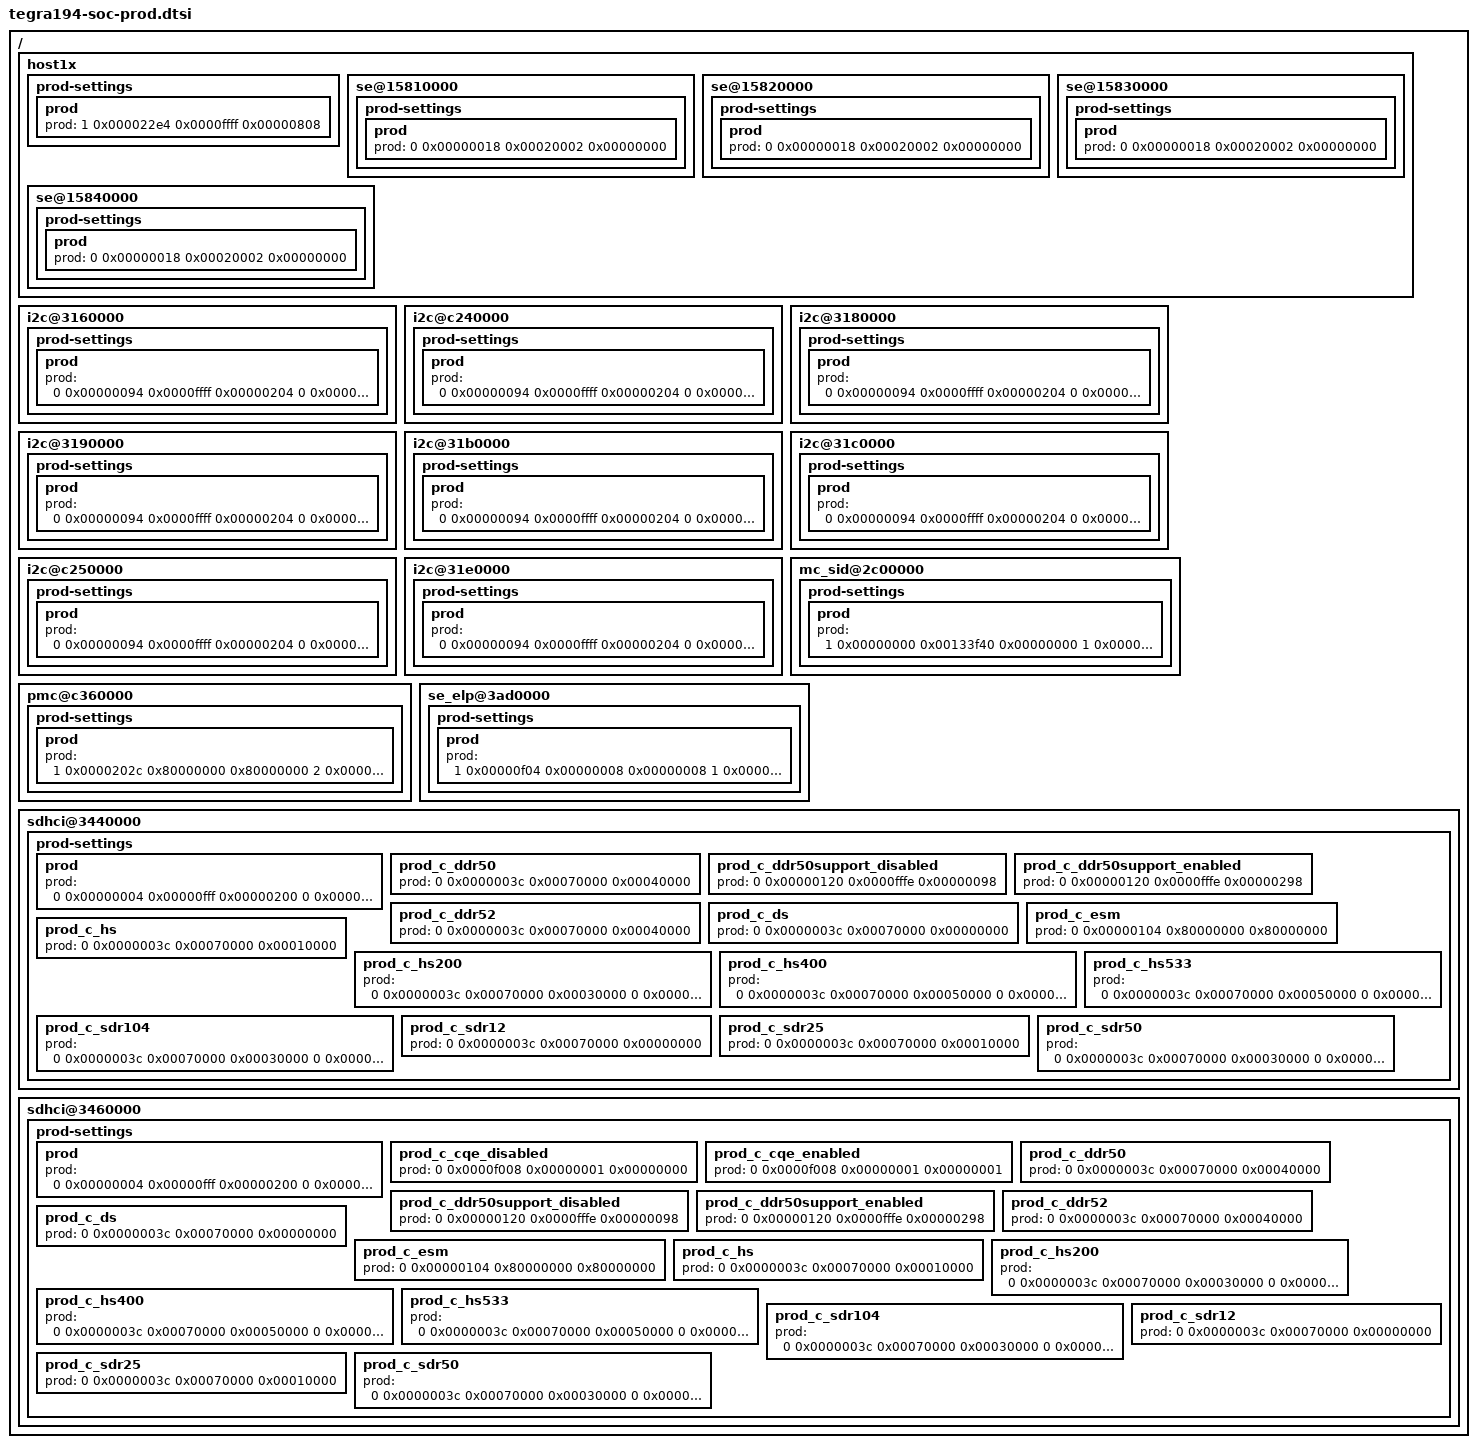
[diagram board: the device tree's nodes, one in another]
/*
 * Copyright (c) 2017, NVIDIA CORPORATION.  All rights reserved.
 *
 * This program is free software; you can redistribute it and/or modify
 * it under the terms of the GNU General Public License as published by
 * the Free Software Foundation; version 2 of the License.
 *
 * This program is distributed in the hope that it will be useful, but WITHOUT
 * ANY WARRANTY; without even the implied warranty of MERCHANTABILITY or
 * FITNESS FOR A PARTICULAR PURPOSE.  See the GNU General Public License for
 * more details.
 *
 * You should have received a copy of the GNU General Public License along
 * with this program; if not, write to the Free Software Foundation, Inc.,
 * 51 Franklin Street, Fifth Floor, Boston, MA  02110-1301, USA.
 *
 */
/*
* tegra194-soc-prod.dtsi: soc specific Prod configuration.
* Generation date: 2017-11-07 12:20
* PLEASE DO NOT EDIT THIS FILE MANUALLY
* This file is autogenerated using the script gen_prod_dtsi.py V1.2
* NOTE: Do not use file as is. Copy the relevant section to existing file in tree.
* NOTE: FIXME nodes indicate nodes corresponding to Golden Register were not found in input DTB.
*       Please check if DTB has the nodes enabled and register address in GR DB is valid.
*/

/ {
	host1x {
		prod-settings {
			#prod-cells = <4>;
			prod {
				prod = <
					1 0x000022e4 0x0000ffff 0x00000808>;            //HOST1X_THOST_COMMON_CDMA_ASM_TIMEOUT_0
			};
		};
		se@15810000 {
			prod-settings {
				#prod-cells = <4>;
				prod {
					prod = <
						0 0x00000018 0x00020002 0x00000000>;            //SE1_SE_SECURITY_0
				};
			};
		};

		se@15820000 {
			prod-settings {
				#prod-cells = <4>;
				prod {
					prod = <
						0 0x00000018 0x00020002 0x00000000>;            //SE2_SE_SECURITY_0
				};
			};
		};

		se@15830000 {
			prod-settings {
				#prod-cells = <4>;
				prod {
					prod = <
						0 0x00000018 0x00020002 0x00000000>;            //SE3_SE_SECURITY_0
				};
			};
		};

		se@15840000 {
			prod-settings {
				#prod-cells = <4>;
				prod {
					prod = <
						0 0x00000018 0x00020002 0x00000000>;            //SE4_SE_SECURITY_0
				};
			};
		};
	};

	i2c@3160000 {
		prod-settings {
			#prod-cells = <4>;
			prod {
				prod = <
					0 0x00000094 0x0000ffff 0x00000204              //I2C_I2C_INTERFACE_TIMING_0_0
					0 0x00000098 0xffffffff 0x04070404              //I2C_I2C_INTERFACE_TIMING_1_0
					0 0x0000009c 0x0000ffff 0x00000308              //I2C_I2C_HS_INTERFACE_TIMING_0_0
					0 0x000000a0 0x00ffffff 0x000b0b0b              //I2C_I2C_HS_INTERFACE_TIMING_1_0
					0 0x000000d4 0x000000ff 0x00000000              //I2C_I2C_INTERFACE_TIMING_2_0
					0 0x000000d8 0x000000ff 0x00000000              //I2C_I2C_HS_INTERFACE_TIMING_2_0
					0 0x000000dc 0x0000ffff 0x00000001              //I2C_I2C_MSTR_DATA_CAPTURE_TIMING_0
					0 0x000000e0 0x0000ffff 0x00000002>;            //I2C_I2C_SLV_DATA_CAPTURE_TIMING_0
			};
		};
	};

	i2c@c240000 {
		prod-settings {
			#prod-cells = <4>;
			prod {
				prod = <
					0 0x00000094 0x0000ffff 0x00000204              //I2C_I2C_INTERFACE_TIMING_0_0
					0 0x00000098 0xffffffff 0x04070404              //I2C_I2C_INTERFACE_TIMING_1_0
					0 0x0000009c 0x0000ffff 0x00000308              //I2C_I2C_HS_INTERFACE_TIMING_0_0
					0 0x000000a0 0x00ffffff 0x000b0b0b              //I2C_I2C_HS_INTERFACE_TIMING_1_0
					0 0x000000d4 0x000000ff 0x00000000              //I2C_I2C_INTERFACE_TIMING_2_0
					0 0x000000d8 0x000000ff 0x00000000              //I2C_I2C_HS_INTERFACE_TIMING_2_0
					0 0x000000dc 0x0000ffff 0x00000001              //I2C_I2C_MSTR_DATA_CAPTURE_TIMING_0
					0 0x000000e0 0x0000ffff 0x00000002>;            //I2C_I2C_SLV_DATA_CAPTURE_TIMING_0
			};
		};
	};

	i2c@3180000 {
		prod-settings {
			#prod-cells = <4>;
			prod {
				prod = <
					0 0x00000094 0x0000ffff 0x00000204              //I2C_I2C_INTERFACE_TIMING_0_0
					0 0x00000098 0xffffffff 0x04070404              //I2C_I2C_INTERFACE_TIMING_1_0
					0 0x0000009c 0x0000ffff 0x00000308              //I2C_I2C_HS_INTERFACE_TIMING_0_0
					0 0x000000a0 0x00ffffff 0x000b0b0b              //I2C_I2C_HS_INTERFACE_TIMING_1_0
					0 0x000000d4 0x000000ff 0x00000000              //I2C_I2C_INTERFACE_TIMING_2_0
					0 0x000000d8 0x000000ff 0x00000000              //I2C_I2C_HS_INTERFACE_TIMING_2_0
					0 0x000000dc 0x0000ffff 0x00000001              //I2C_I2C_MSTR_DATA_CAPTURE_TIMING_0
					0 0x000000e0 0x0000ffff 0x00000002>;            //I2C_I2C_SLV_DATA_CAPTURE_TIMING_0
			};
		};
	};

	i2c@3190000 {
		prod-settings {
			#prod-cells = <4>;
			prod {
				prod = <
					0 0x00000094 0x0000ffff 0x00000204              //I2C_I2C_INTERFACE_TIMING_0_0
					0 0x00000098 0xffffffff 0x04070404              //I2C_I2C_INTERFACE_TIMING_1_0
					0 0x0000009c 0x0000ffff 0x00000308              //I2C_I2C_HS_INTERFACE_TIMING_0_0
					0 0x000000a0 0x00ffffff 0x000b0b0b              //I2C_I2C_HS_INTERFACE_TIMING_1_0
					0 0x000000d4 0x000000ff 0x00000000              //I2C_I2C_INTERFACE_TIMING_2_0
					0 0x000000d8 0x000000ff 0x00000000              //I2C_I2C_HS_INTERFACE_TIMING_2_0
					0 0x000000dc 0x0000ffff 0x00000001              //I2C_I2C_MSTR_DATA_CAPTURE_TIMING_0
					0 0x000000e0 0x0000ffff 0x00000002>;            //I2C_I2C_SLV_DATA_CAPTURE_TIMING_0
			};
		};
	};

	i2c@31b0000 {
		prod-settings {
			#prod-cells = <4>;
			prod {
				prod = <
					0 0x00000094 0x0000ffff 0x00000204              //I2C_I2C_INTERFACE_TIMING_0_0
					0 0x00000098 0xffffffff 0x04070404              //I2C_I2C_INTERFACE_TIMING_1_0
					0 0x0000009c 0x0000ffff 0x00000308              //I2C_I2C_HS_INTERFACE_TIMING_0_0
					0 0x000000a0 0x00ffffff 0x000b0b0b              //I2C_I2C_HS_INTERFACE_TIMING_1_0
					0 0x000000d4 0x000000ff 0x00000000              //I2C_I2C_INTERFACE_TIMING_2_0
					0 0x000000d8 0x000000ff 0x00000000              //I2C_I2C_HS_INTERFACE_TIMING_2_0
					0 0x000000dc 0x0000ffff 0x00000001              //I2C_I2C_MSTR_DATA_CAPTURE_TIMING_0
					0 0x000000e0 0x0000ffff 0x00000002>;            //I2C_I2C_SLV_DATA_CAPTURE_TIMING_0
			};
		};
	};

	i2c@31c0000 {
		prod-settings {
			#prod-cells = <4>;
			prod {
				prod = <
					0 0x00000094 0x0000ffff 0x00000204              //I2C_I2C_INTERFACE_TIMING_0_0
					0 0x00000098 0xffffffff 0x04070404              //I2C_I2C_INTERFACE_TIMING_1_0
					0 0x0000009c 0x0000ffff 0x00000308              //I2C_I2C_HS_INTERFACE_TIMING_0_0
					0 0x000000a0 0x00ffffff 0x000b0b0b              //I2C_I2C_HS_INTERFACE_TIMING_1_0
					0 0x000000d4 0x000000ff 0x00000000              //I2C_I2C_INTERFACE_TIMING_2_0
					0 0x000000d8 0x000000ff 0x00000000              //I2C_I2C_HS_INTERFACE_TIMING_2_0
					0 0x000000dc 0x0000ffff 0x00000001              //I2C_I2C_MSTR_DATA_CAPTURE_TIMING_0
					0 0x000000e0 0x0000ffff 0x00000002>;            //I2C_I2C_SLV_DATA_CAPTURE_TIMING_0
			};
		};
	};

	i2c@c250000 {
		prod-settings {
			#prod-cells = <4>;
			prod {
				prod = <
					0 0x00000094 0x0000ffff 0x00000204              //I2C_I2C_INTERFACE_TIMING_0_0
					0 0x00000098 0xffffffff 0x04070404              //I2C_I2C_INTERFACE_TIMING_1_0
					0 0x0000009c 0x0000ffff 0x00000308              //I2C_I2C_HS_INTERFACE_TIMING_0_0
					0 0x000000a0 0x00ffffff 0x000b0b0b              //I2C_I2C_HS_INTERFACE_TIMING_1_0
					0 0x000000d4 0x000000ff 0x00000000              //I2C_I2C_INTERFACE_TIMING_2_0
					0 0x000000d8 0x000000ff 0x00000000              //I2C_I2C_HS_INTERFACE_TIMING_2_0
					0 0x000000dc 0x0000ffff 0x00000001              //I2C_I2C_MSTR_DATA_CAPTURE_TIMING_0
					0 0x000000e0 0x0000ffff 0x00000002>;            //I2C_I2C_SLV_DATA_CAPTURE_TIMING_0
			};
		};
	};

	i2c@31e0000 {
		prod-settings {
			#prod-cells = <4>;
			prod {
				prod = <
					0 0x00000094 0x0000ffff 0x00000204              //I2C_I2C_INTERFACE_TIMING_0_0
					0 0x00000098 0xffffffff 0x04070404              //I2C_I2C_INTERFACE_TIMING_1_0
					0 0x0000009c 0x0000ffff 0x00000308              //I2C_I2C_HS_INTERFACE_TIMING_0_0
					0 0x000000a0 0x00ffffff 0x000b0b0b              //I2C_I2C_HS_INTERFACE_TIMING_1_0
					0 0x000000d4 0x000000ff 0x00000000              //I2C_I2C_INTERFACE_TIMING_2_0
					0 0x000000d8 0x000000ff 0x00000000              //I2C_I2C_HS_INTERFACE_TIMING_2_0
					0 0x000000dc 0x0000ffff 0x00000001              //I2C_I2C_MSTR_DATA_CAPTURE_TIMING_0
					0 0x000000e0 0x0000ffff 0x00000002>;            //I2C_I2C_SLV_DATA_CAPTURE_TIMING_0
			};
		};
	};

	mc_sid@2c00000 {
		prod-settings {
			#prod-cells = <4>;
			prod {
				prod = <
					1 0x00000000 0x00133f40 0x00000000              //MC_INTSTATUS_0
					1 0x00000004 0x001f3f40 0x00000000              //MC_INTMASK_0
					1 0x00000010 0x00000001 0x00000000              //MC_SMMU_CONFIG_0
					1 0x00000014 0xf000003f 0x30000030              //MC_SMMU_TLB_CONFIG_0
					1 0x00000018 0xe03f0fff 0x20220f3f              //MC_SMMU_PTC_CONFIG_0
					1 0x00000030 0x00100000 0x00000000              //MC_SMMU_TLB_FLUSH_0
					1 0x00000034 0x00000008 0x00000008              //MC_SMMU_PTC_FLUSH_0
					1 0x00000038 0xffffffff 0x00000000              //MC_SMMU_ASID_SECURITY_0
					1 0x00000050 0x80000000 0x00000000              //MC_EMEM_CFG_0
					1 0x00000070 0xfff00000 0x80000000              //MC_SECURITY_CFG0_0
					1 0x00000074 0x00001fff 0x00000000              //MC_SECURITY_CFG1_0
					1 0x0000007c 0xffffffff 0xff00ff00              //MC_SECURITY_RSV_0
					1 0x00000090 0xff000000 0x00000000              //MC_EMEM_ARB_CFG_0
					1 0x000000bc 0x0000003f 0x0000003f              //MC_EMEM_ARB_TIMING_W2W_0
					1 0x000000c8 0xf0ff0ffe 0xb00a0402              //MC_EMEM_ARB_MISC2_0
					1 0x000000cc 0x00000003 0x00000000              //MC_CLKEN_A1_OVERRIDE_0
					1 0x000000d8 0x7fe080ff 0x72000010              //MC_EMEM_ARB_MISC0_0
					1 0x000000dc 0x0000fffd 0x00000008              //MC_EMEM_ARB_MISC1_0
					1 0x000000e0 0x003f003f 0x003f0000              //MC_EMEM_ARB_RING1_THROTTLE_0
					1 0x000000e4 0x001f001f 0x00000000              //MC_EMEM_ARB_RING3_THROTTLE_0
					1 0x000000e8 0x8cffff18 0x00000000              //MC_EMEM_ARB_OVERRIDE_0
					1 0x000000ec 0xffffffff 0xff00ff00              //MC_EMEM_ARB_RSV_0
					1 0x000000f4 0xffffffed 0x00000000              //MC_CLKEN_OVERRIDE_0
					1 0x000000f8 0x0000001f 0x00000000              //MC_TIMING_CONTROL_DBG_0
					1 0x00000154 0x00000001 0x00000000              //MC_SECURITY_CFG_REG_CTRL_0
					1 0x000001c0 0x00007f33 0x00000030              //MC_STAT_EMC_SET0_IDLE_CYCLE_PARTITION_SELECT_0
					1 0x000001d0 0x00007f33 0x00000030              //MC_STAT_EMC_SET1_IDLE_CYCLE_PARTITION_SELECT_0
					1 0x000001ec 0x8000ffff 0x80000000              //MC_SMMU_STATS_TLB_HIT_MISS_SOURCE_0
					1 0x0000023c 0xf0ff7f7f 0xf0551010              //MC_EMEM_ARB_MISC3_0
					1 0x00000240 0x0000f7ff 0x00007010              //MC_EMEM_ARB_MISC4_0
					1 0x000003fc 0xf0000000 0xf0000000              //MC_RESERVED_RSV_0
					1 0x00000564 0x0fffffff 0x00000000              //MC_IGPU_ACCESSIBLE_CARVEOUT1_SIZE_0
					1 0x0000056c 0x0fffffff 0x00000000              //MC_IGPU_ACCESSIBLE_CARVEOUT2_SIZE_0
					1 0x000005a4 0x0fffffff 0x00000000              //MC_REMOTE_DEV_ACCESSIBLE_CARVEOUT1_SIZE_0
					1 0x000005ac 0x0fffffff 0x00000000              //MC_REMOTE_DEV_ACCESSIBLE_CARVEOUT2_SIZE_0
					1 0x0000066c 0xc00003ff 0x80000080              //MC_EMEM_ARB_OUTSTANDING_REQ_RING3_0
					1 0x000006b0 0x803f003f 0x003f0000              //MC_EMEM_ARB_NISO_THROTTLE_0
					1 0x000006b4 0xc00003ff 0x00000080              //MC_EMEM_ARB_OUTSTANDING_REQ_NISO_0
					1 0x000006bc 0x800080c5 0x80008041              //MC_EMEM_ARB_RING0_THROTTLE_MASK_0
					1 0x000006f0 0x007f7f7f 0x000a1020              //MC_EMEM_ARB_REFPB_HP_CTRL_0
					1 0x000006f4 0x00007f7f 0x00002636              //MC_EMEM_ARB_REFPB_BANK_CTRL_0
					1 0x00000958 0xffffffff 0xff00ff00              //MC_RESERVED_RSV_1_0
					1 0x00000960 0x00001fff 0x00001000              //MC_PTSA_GRANT_DECREMENT_0
					1 0x00000968 0x000018a0 0x00000080              //MC_EMEM_ARB_OVERRIDE_1_0
					1 0x00000984 0xffffffff 0x00000000              //MC_VIDEO_PROTECT_GPU_OVERRIDE_0_0
					1 0x00000988 0x0000ffff 0x00000000              //MC_VIDEO_PROTECT_GPU_OVERRIDE_1_0
					1 0x00000990 0x003f003f 0x003f0004              //MC_EMEM_ARB_STATS_0_0
					1 0x00000994 0x003f003f 0x003f0004              //MC_EMEM_ARB_STATS_1_0
					1 0x000009a4 0x00000fff 0x00000000              //MC_MTS_CARVEOUT_SIZE_MB_0
					1 0x000009bc 0x000000ff 0x00000000              //MC_SECURITY_CFG3_0
					1 0x000009d0 0x00030000 0x00000000              //MC_ERR_APB_ASID_UPDATE_STATUS_0
					1 0x000009fc 0xb790f3ff 0x9680f183              //MC_EMEM_ARB_DA_HYSTERESIS_0
					1 0x00000bcc 0x00000003 0x00000002              //MC_EMEM_ARB_DHYST_CTRL_0
					1 0x00000bd0 0x00000fff 0x00000100              //MC_EMEM_ARB_DHYST_TIMEOUT_UTIL_0_0
					1 0x00000bd4 0x00000fff 0x000000a0              //MC_EMEM_ARB_DHYST_TIMEOUT_UTIL_1_0
					1 0x00000bd8 0x00000fff 0x00000060              //MC_EMEM_ARB_DHYST_TIMEOUT_UTIL_2_0
					1 0x00000bdc 0x00000fff 0x00000034              //MC_EMEM_ARB_DHYST_TIMEOUT_UTIL_3_0
					1 0x00000be0 0x00000fff 0x00000018              //MC_EMEM_ARB_DHYST_TIMEOUT_UTIL_4_0
					1 0x00000be4 0x00000fff 0x0000000c              //MC_EMEM_ARB_DHYST_TIMEOUT_UTIL_5_0
					1 0x00000be8 0x00000fff 0x00000004              //MC_EMEM_ARB_DHYST_TIMEOUT_UTIL_6_0
					1 0x00000bec 0x00000fff 0x00000000              //MC_EMEM_ARB_DHYST_TIMEOUT_UTIL_7_0
					1 0x00000e54 0x00080200 0x00000000              //MC_CH_INTSTATUS_0
					1 0x00000e5c 0x000007ff 0x00000003              //MC_LATENCY_ALLOWANCE_WCAM_0
					1 0x00000e60 0x00010000 0x00010000              //MC_CFG_WCAM_0
					1 0x00000e64 0xff0f0f0f 0x00000000              //MC_WCAM_ENCR_KEY_STATUS_0
					1 0x00000eb0 0x00000081 0x00000001              //MC_WCAM_STATE_0
					1 0x00000ec4 0x001f3f40 0x00000000              //MC_INTPRIORITY_0
					1 0x00000ed0 0x00000002 0x00000000              //MC_TR_BIT_CTL_0
					1 0x00000ed4 0x00000001 0x00000000              //MC_CFG_WCAM_GOB_REMAP_0
					1 0x00000edc 0x7f7f0001 0x00000000              //MC_WCAM_IRQ_TEST_0
					1 0x00000ee0 0x0fffffff 0x00000000              //MC_WCAM_IRQ_P0_STATUS0_0
					1 0x00000ee4 0xfffffff8 0x00000000              //MC_WCAM_IRQ_P0_STATUS1_0
					1 0x00000ee8 0x0fffffff 0x00000000              //MC_WCAM_IRQ_P1_STATUS0_0
					1 0x00000eec 0xfffffff8 0x00000000              //MC_WCAM_IRQ_P1_STATUS1_0
					1 0x00000f24 0x07ff0fff 0x00000000              //MC_GLOBAL_INTSTATUS_0
					1 0x00000f28 0x03ff0fff 0x00000000              //MC_GLOBAL_CRITICAL_INTSTATUS_0
					1 0x00000f2c 0x00000001 0x00000000              //MC_HUBC_INTSTATUS_0
					1 0x00000f38 0xe03f1fff 0x20221f3f              //MC_SMMU_NVCACHE_CONFIG_0
					1 0x00000f3c 0x00000001 0x00000000              //MC_CCITRX_ENABLE_CONFIG_0
					1 0x00000f40 0x000000ff 0x00000080              //MC_CCI_WR_LATENCY_ALLOWANCE_CONFIG_0
					1 0x00000f48 0x000007ff 0x00000000              //MC_SMMU_NVCACHE_ALLOWANCE_0
					1 0x00000f4c 0x00000007 0x00000001              //MC_SMMU_TCU_WRAP_CONFIG_0
					1 0x00000f50 0x00000003 0x00000000              //MC_HUB_INTMASK_0
					1 0x00000f54 0x00000003 0x00000000              //MC_HUB_INTPRIORITY_0
					1 0x00000f58 0x00000003 0x00000000              //MC_HUB_INTSTATUS_0
					1 0x00000f60 0x8000000f 0x80000000              //MC_CIFLL_MISC0_0
					1 0x00000f64 0x800f0fff 0x800c0019              //MC_CIFLL_REDEADLINE0_0
					1 0x00000f68 0x800f0fff 0x800c0004              //MC_CIFLL_REDEADLINE1_0
					1 0x00000fa0 0x00000001 0x00000000              //MC_HUB_CLKEN_OVERRIDE_0
					1 0x00000fa4 0x3fffffff 0x16286840              //MC_HUB_VCTHROTTLE_OVERRIDE_0
					1 0x00000fe8 0x00000001 0x00000001              //MC_CONFIG_TSA_SINGLE_ARB_ENABLE_0
					1 0x00000fec 0x00000007 0x00000007              //MC_DBB_RINGFENCE_CTRL_0
					1 0x00001840 0x800003ff 0x8000006e              //MC_MAX_OUTSTANDING_CCI_0
					1 0x00001850 0xfffff000 0x40000000              //MC_SYSRAM_BOM_0
					1 0x00001854 0xfffff000 0x40067000              //MC_SYSRAM_TOM_0
					1 0x00001860 0x000fffff 0x00020000              //MC_MSSNVLINK_BOM_0
					1 0x00001864 0x000fffff 0x00000000              //MC_MSSNVLINK_TOM_0
					1 0x00001870 0x000fffff 0x00000600              //MC_SYNCPOINT_BOM_0
					1 0x00001874 0x000fffff 0x00000603              //MC_SYNCPOINT_TOM_0
					1 0x00001890 0x000007ff 0x00000020              //MC_MSSNVLINK_IGPU_LATENCY_ALLOWANCE_0
					1 0x00001894 0x000007ff 0x00000020              //MC_MSSNVLINK_DGPU_LATENCY_ALLOWANCE_0
					1 0x0000189c 0x000007ff 0x00000000              //MC_CIFLL_NVLRHP_LATENCY_ALLOWANCE_0
					1 0x000018b8 0x00000001 0x00000001              //MC_MC_TBU_TRANSACTION_ATTR_CTRL_0
					1 0x0000193c 0x00000003 0x00000000              //MC_CLIENT_CCI_CAPABLE_7_0
					1 0x00001b00 0xffffffff 0x00000000              //MC_HUB_STATS_PM_COUNT0WORD0_0
					1 0x00002958 0x800003ff 0x00000040              //MC_MC_SMMU_ARB_MAX_OUTSTANDING_NISO_0
					1 0x0000295c 0x800003ff 0x00000040              //MC_MC_SMMU_ARB_MAX_OUTSTANDING_SISO_0
					1 0x00002960 0x800003ff 0x00000040              //MC_MC_SMMU_ARB_MAX_OUTSTANDING_ISO_0
					1 0x00002964 0x0000007f 0x0000003f              //MC_MC_SMMU_ARB_MAX_THROTTLE_0
					1 0x00002968 0x00000301 0x00000001              //MC_MC_SMMU_ISO_TBU_CCHK_REQ_PRI_CTRL_0
					1 0x000037e0 0x000000ff 0x00000000              //MC_GLOBAL_INTSTATUS_1_0
					1 0x000037e4 0x000000ff 0x00000000              //MC_GLOBAL_CRITICAL_INTSTATUS_1_0
					1 0x00008010 0x0000001f 0x00000000              //MC_MCF_ORSPX_CLKEN_OVERRIDE_0
					1 0x00008014 0x00007fff 0x00000000              //MC_MCF_IRSPX_CLKEN_OVERRIDE_0
					1 0x00008114 0x0000003f 0x00000000              //MC_MCF_IREQX_CLKEN_OVERRIDE_0
					1 0x00008118 0x0000003f 0x00000000              //MC_MCF_OREQX_CLKEN_OVERRIDE_0
					1 0x00008300 0x00070003 0x00020000              //MC_MCF_SLICE_CFG_0
					1 0x00008324 0x0000003f 0x00000000              //MC_MCF_SLICE_CLKEN_OVERRIDE_0
					1 0x00008c04 0x0000000f 0x00000000              //MC_MSS_SYSRAM_CLKEN_OVERRIDE_0
					1 0x00008f08 0x00000007 0x00000000              //MC_MSS_SBS_INTSTATUS_0
					1 0x00008f0c 0x00000007 0x00000000              //MC_MSS_SBS_INTMASK_0
					1 0x00008f10 0x00000007 0x00000000>;            //MC_MSS_SBS_CLKEN_OVERRIDE_0
			};
		};
	};

	pmc@c360000 {
		prod-settings {
			#prod-cells = <4>;
			prod {
				prod = <
					1 0x0000202c 0x80000000 0x80000000              //SCRATCH_SCRATCH0_ECO_0
					2 0x00000010 0x00000001 0x00000001>;            //PMC_MISC_FUSE_CONTROL_0
			};
		};
	};

	se_elp@3ad0000 {
		prod-settings {
			#prod-cells = <4>;
			prod {
				prod = <
					1 0x00000f04 0x00000008 0x00000008              //SE_RNG1_RNG1_MODE_0
					1 0x00000f08 0x00000002 0x00000002              //SE_RNG1_RNG1_SMODE_0
					1 0x00000fec 0x00000002 0x00000000>;            //SE_RNG1_RNG1_SECURITY_0
			};
		};
	};

	sdhci@3440000 {
		prod-settings {
			#prod-cells = <4>;
			prod {
				prod = <
					0 0x00010004 0x00000fff 0x00000200              //SDMMC_BLOCK_SIZE_BLOCK_COUNT_0
					0 0x00010028 0x00000022 0x00000002              //SDMMC_POWER_CONTROL_HOST_0
					0 0x0001002c 0x000f0000 0x000e0000              //SDMMC_SW_RESET_TIMEOUT_CTRL_CLOCK_CONTROL_0
					0 0x00010100 0x1fff0048 0x050b0000              //SDMMC_VENDOR_CLOCK_CNTRL_0
					0 0x00010104 0x80000000 0x00000000              //SDMMC_VENDOR_SYS_SW_CNTRL_0
					0 0x00010128 0x42000000 0x00000000              //SDMMC_VENDOR_MISC_CNTRL2_0
					0 0x000101c0 0x00001fc0 0x00000040              //SDMMC_VENDOR_TUNING_CNTRL0_0
					0 0x000101c4 0x0003ff77 0x00000400              //SDMMC_VENDOR_TUNING_CNTRL1_0
					0 0x000101e0 0x80000000 0x00000000              //SDMMC_SDMEMCOMPPADCTRL_0
					0 0x000101e4 0x20007f00 0x20007a00              //SDMMC_AUTO_CAL_CONFIG_0
					0 0x00010204 0x80000000 0x00000000>;            //SDMMC_VENDOR_MISC_CNTRL3_0
			};
			prod_c_ddr50 {
				prod = <
					0 0x0001003c 0x00070000 0x00040000>;            //SDMMC_AUTO_CMD12_ERR_STATUS_0
			};
			prod_c_ddr50support_disabled {
				prod = <
					0 0x00010120 0x0000fffe 0x00000098>;            //SDMMC_VENDOR_MISC_CNTRL_0
			};
			prod_c_ddr50support_enabled {
				prod = <
					0 0x00010120 0x0000fffe 0x00000298>;            //SDMMC_VENDOR_MISC_CNTRL_0
			};
			prod_c_ddr52 {
				prod = <
					0 0x0001003c 0x00070000 0x00040000>;            //SDMMC_AUTO_CMD12_ERR_STATUS_0
			};
			prod_c_ds {
				prod = <
					0 0x0001003c 0x00070000 0x00000000>;            //SDMMC_AUTO_CMD12_ERR_STATUS_0
			};
			prod_c_esm {
				prod = <
					0 0x00010104 0x80000000 0x80000000>;            //SDMMC_VENDOR_SYS_SW_CNTRL_0
			};
			prod_c_hs {
				prod = <
					0 0x0001003c 0x00070000 0x00010000>;            //SDMMC_AUTO_CMD12_ERR_STATUS_0
			};
			prod_c_hs200 {
				prod = <
					0 0x0001003c 0x00070000 0x00030000              //SDMMC_AUTO_CMD12_ERR_STATUS_0
					0 0x000101c0 0x0000e000 0x00004000>;            //SDMMC_VENDOR_TUNING_CNTRL0_0
			};
			prod_c_hs400 {
				prod = <
					0 0x0001003c 0x00070000 0x00050000              //SDMMC_AUTO_CMD12_ERR_STATUS_0
					0 0x00010100 0x00000008 0x00000008              //SDMMC_VENDOR_CLOCK_CNTRL_0
					0 0x0001010c 0x00003f00 0x00003f00              //SDMMC_VENDOR_CAP_OVERRIDES_0
					0 0x000101c0 0x0000e000 0x00004000              //SDMMC_VENDOR_TUNING_CNTRL0_0
					0 0x000101e4 0x00007f7f 0x00000505>;            //SDMMC_AUTO_CAL_CONFIG_0
			};
			prod_c_hs533 {
				prod = <
					0 0x0001003c 0x00070000 0x00050000              //SDMMC_AUTO_CMD12_ERR_STATUS_0
					0 0x00010100 0x00000008 0x00000008              //SDMMC_VENDOR_CLOCK_CNTRL_0
					0 0x0001010c 0x00003f00 0x00002800              //SDMMC_VENDOR_CAP_OVERRIDES_0
					0 0x000101c0 0x0000e000 0x00002000              //SDMMC_VENDOR_TUNING_CNTRL0_0
					0 0x000101e4 0x00007f7f 0x00000505>;            //SDMMC_AUTO_CAL_CONFIG_0
			};
			prod_c_sdr104 {
				prod = <
					0 0x0001003c 0x00070000 0x00030000              //SDMMC_AUTO_CMD12_ERR_STATUS_0
					0 0x000101c0 0x0000e000 0x00004000>;            //SDMMC_VENDOR_TUNING_CNTRL0_0
			};
			prod_c_sdr12 {
				prod = <
					0 0x0001003c 0x00070000 0x00000000>;            //SDMMC_AUTO_CMD12_ERR_STATUS_0
			};
			prod_c_sdr25 {
				prod = <
					0 0x0001003c 0x00070000 0x00010000>;            //SDMMC_AUTO_CMD12_ERR_STATUS_0
			};
			prod_c_sdr50 {
				prod = <
					0 0x0001003c 0x00070000 0x00030000              //SDMMC_AUTO_CMD12_ERR_STATUS_0
					0 0x000101c0 0x0000e000 0x00008000>;            //SDMMC_VENDOR_TUNING_CNTRL0_0
			};
		};
	};

	sdhci@3440000 {
		prod-settings {
			#prod-cells = <4>;
			prod {
				prod = <
					0 0x00000004 0x00000fff 0x00000200              //SDMMC_BLOCK_SIZE_BLOCK_COUNT_0
					0 0x00000028 0x00000022 0x00000002              //SDMMC_POWER_CONTROL_HOST_0
					0 0x0000002c 0x000f0000 0x000e0000              //SDMMC_SW_RESET_TIMEOUT_CTRL_CLOCK_CONTROL_0
					0 0x00000100 0x1fff0048 0x050b0000              //SDMMC_VENDOR_CLOCK_CNTRL_0
					0 0x00000104 0x80000000 0x00000000              //SDMMC_VENDOR_SYS_SW_CNTRL_0
					0 0x00000128 0x42000000 0x00000000              //SDMMC_VENDOR_MISC_CNTRL2_0
					0 0x000001c0 0x00001fc0 0x00000040              //SDMMC_VENDOR_TUNING_CNTRL0_0
					0 0x000001c4 0x0003ff77 0x00000400              //SDMMC_VENDOR_TUNING_CNTRL1_0
					0 0x000001e0 0x80000000 0x00000000              //SDMMC_SDMEMCOMPPADCTRL_0
					0 0x000001e4 0x20007f00 0x20007a00              //SDMMC_AUTO_CAL_CONFIG_0
					0 0x00000204 0x80000000 0x00000000>;            //SDMMC_VENDOR_MISC_CNTRL3_0
			};
			prod_c_ddr50 {
				prod = <
					0 0x0000003c 0x00070000 0x00040000>;            //SDMMC_AUTO_CMD12_ERR_STATUS_0
			};
			prod_c_ddr50support_disabled {
				prod = <
					0 0x00000120 0x0000fffe 0x00000098>;            //SDMMC_VENDOR_MISC_CNTRL_0
			};
			prod_c_ddr50support_enabled {
				prod = <
					0 0x00000120 0x0000fffe 0x00000298>;            //SDMMC_VENDOR_MISC_CNTRL_0
			};
			prod_c_ddr52 {
				prod = <
					0 0x0000003c 0x00070000 0x00040000>;            //SDMMC_AUTO_CMD12_ERR_STATUS_0
			};
			prod_c_ds {
				prod = <
					0 0x0000003c 0x00070000 0x00000000>;            //SDMMC_AUTO_CMD12_ERR_STATUS_0
			};
			prod_c_esm {
				prod = <
					0 0x00000104 0x80000000 0x80000000>;            //SDMMC_VENDOR_SYS_SW_CNTRL_0
			};
			prod_c_hs {
				prod = <
					0 0x0000003c 0x00070000 0x00010000>;            //SDMMC_AUTO_CMD12_ERR_STATUS_0
			};
			prod_c_hs200 {
				prod = <
					0 0x0000003c 0x00070000 0x00030000              //SDMMC_AUTO_CMD12_ERR_STATUS_0
					0 0x000001c0 0x0000e000 0x00004000>;            //SDMMC_VENDOR_TUNING_CNTRL0_0
			};
			prod_c_hs400 {
				prod = <
					0 0x0000003c 0x00070000 0x00050000              //SDMMC_AUTO_CMD12_ERR_STATUS_0
					0 0x00000100 0x00000008 0x00000008              //SDMMC_VENDOR_CLOCK_CNTRL_0
					0 0x0000010c 0x00003f00 0x00003f00              //SDMMC_VENDOR_CAP_OVERRIDES_0
					0 0x000001c0 0x0000e000 0x00004000              //SDMMC_VENDOR_TUNING_CNTRL0_0
					0 0x000001e4 0x00007f7f 0x00000505>;            //SDMMC_AUTO_CAL_CONFIG_0
			};
			prod_c_hs533 {
				prod = <
					0 0x0000003c 0x00070000 0x00050000              //SDMMC_AUTO_CMD12_ERR_STATUS_0
					0 0x00000100 0x00000008 0x00000008              //SDMMC_VENDOR_CLOCK_CNTRL_0
					0 0x0000010c 0x00003f00 0x00002800              //SDMMC_VENDOR_CAP_OVERRIDES_0
					0 0x000001c0 0x0000e000 0x00002000              //SDMMC_VENDOR_TUNING_CNTRL0_0
					0 0x000001e4 0x00007f7f 0x00000505>;            //SDMMC_AUTO_CAL_CONFIG_0
			};
			prod_c_sdr104 {
				prod = <
					0 0x0000003c 0x00070000 0x00030000              //SDMMC_AUTO_CMD12_ERR_STATUS_0
					0 0x000001c0 0x0000e000 0x00004000>;            //SDMMC_VENDOR_TUNING_CNTRL0_0
			};
			prod_c_sdr12 {
				prod = <
					0 0x0000003c 0x00070000 0x00000000>;            //SDMMC_AUTO_CMD12_ERR_STATUS_0
			};
			prod_c_sdr25 {
				prod = <
					0 0x0000003c 0x00070000 0x00010000>;            //SDMMC_AUTO_CMD12_ERR_STATUS_0
			};
			prod_c_sdr50 {
				prod = <
					0 0x0000003c 0x00070000 0x00030000              //SDMMC_AUTO_CMD12_ERR_STATUS_0
					0 0x000001c0 0x0000e000 0x00008000>;            //SDMMC_VENDOR_TUNING_CNTRL0_0
			};
		};
	};

	sdhci@3460000 {
		prod-settings {
			#prod-cells = <4>;
			prod {
				prod = <
					0 0x00010004 0x00000fff 0x00000200              //SDMMCAB_BLOCK_SIZE_BLOCK_COUNT_0
					0 0x00010028 0x00000020 0x00000020              //SDMMCAB_POWER_CONTROL_HOST_0
					0 0x0001002c 0x000f0000 0x000e0000              //SDMMCAB_SW_RESET_TIMEOUT_CTRL_CLOCK_CONTROL_0
					0 0x00010100 0x1fff0048 0x05090000              //SDMMCAB_VENDOR_CLOCK_CNTRL_0
					0 0x00010104 0x80000000 0x00000000              //SDMMCAB_VENDOR_SYS_SW_CNTRL_0
					0 0x00010128 0x43000000 0x00000000              //SDMMCAB_VENDOR_MISC_CNTRL2_0
					0 0x000101c0 0x00001fc0 0x00000040              //SDMMCAB_VENDOR_TUNING_CNTRL0_0
					0 0x000101c4 0x0003ff77 0x00000400              //SDMMCAB_VENDOR_TUNING_CNTRL1_0
					0 0x000101e0 0x80000000 0x00000000              //SDMMCAB_SDMEMCOMPPADCTRL_0
					0 0x000101e4 0x20000000 0x20000000              //SDMMCAB_AUTO_CAL_CONFIG_0
					0 0x00010204 0x80000000 0x00000000              //SDMMCAB_VENDOR_MISC_CNTRL3_0
					0 0x00010218 0x80000000 0x00000000>;            //SDMMCAB_VENDOR_CQE_CNTRL1_0
			};
			prod_c_cqe_disabled {
				prod = <
					0 0x0001f008 0x00000001 0x00000000>;            //SDMMCAB_CQE_CQCFG_0
			};
			prod_c_cqe_enabled {
				prod = <
					0 0x0001f008 0x00000001 0x00000001>;            //SDMMCAB_CQE_CQCFG_0
			};
			prod_c_ddr50 {
				prod = <
					0 0x0001003c 0x00070000 0x00040000>;            //SDMMCAB_AUTO_CMD12_ERR_STATUS_0
			};
			prod_c_ddr50support_disabled {
				prod = <
					0 0x00010120 0x0000fffe 0x00000098>;            //SDMMCAB_VENDOR_MISC_CNTRL_0
			};
			prod_c_ddr50support_enabled {
				prod = <
					0 0x00010120 0x0000fffe 0x00000298>;            //SDMMCAB_VENDOR_MISC_CNTRL_0
			};
			prod_c_ddr52 {
				prod = <
					0 0x0001003c 0x00070000 0x00040000>;            //SDMMCAB_AUTO_CMD12_ERR_STATUS_0
			};
			prod_c_ds {
				prod = <
					0 0x0001003c 0x00070000 0x00000000>;            //SDMMCAB_AUTO_CMD12_ERR_STATUS_0
			};
			prod_c_esm {
				prod = <
					0 0x00010104 0x80000000 0x80000000>;            //SDMMCAB_VENDOR_SYS_SW_CNTRL_0
			};
			prod_c_hs {
				prod = <
					0 0x0001003c 0x00070000 0x00010000>;            //SDMMCAB_AUTO_CMD12_ERR_STATUS_0
			};
			prod_c_hs200 {
				prod = <
					0 0x0001003c 0x00070000 0x00030000              //SDMMCAB_AUTO_CMD12_ERR_STATUS_0
					0 0x000101c0 0x0000e000 0x00004000>;            //SDMMCAB_VENDOR_TUNING_CNTRL0_0
			};
			prod_c_hs400 {
				prod = <
					0 0x0001003c 0x00070000 0x00050000              //SDMMCAB_AUTO_CMD12_ERR_STATUS_0
					0 0x00010100 0x00000008 0x00000008              //SDMMCAB_VENDOR_CLOCK_CNTRL_0
					0 0x0001010c 0x00003f00 0x00003f00              //SDMMCAB_VENDOR_CAP_OVERRIDES_0
					0 0x000101c0 0x0000e000 0x00004000              //SDMMCAB_VENDOR_TUNING_CNTRL0_0
					0 0x000101e4 0x00007f7f 0x00000505>;            //SDMMCAB_AUTO_CAL_CONFIG_0
			};
			prod_c_hs533 {
				prod = <
					0 0x0001003c 0x00070000 0x00050000              //SDMMCAB_AUTO_CMD12_ERR_STATUS_0
					0 0x00010100 0x00000008 0x00000008              //SDMMCAB_VENDOR_CLOCK_CNTRL_0
					0 0x0001010c 0x00003f00 0x00002800              //SDMMCAB_VENDOR_CAP_OVERRIDES_0
					0 0x000101c0 0x0000e000 0x00002000              //SDMMCAB_VENDOR_TUNING_CNTRL0_0
					0 0x000101e4 0x00007f7f 0x00000505>;            //SDMMCAB_AUTO_CAL_CONFIG_0
			};
			prod_c_sdr104 {
				prod = <
					0 0x0001003c 0x00070000 0x00030000              //SDMMCAB_AUTO_CMD12_ERR_STATUS_0
					0 0x000101c0 0x0000e000 0x00004000>;            //SDMMCAB_VENDOR_TUNING_CNTRL0_0
			};
			prod_c_sdr12 {
				prod = <
					0 0x0001003c 0x00070000 0x00000000>;            //SDMMCAB_AUTO_CMD12_ERR_STATUS_0
			};
			prod_c_sdr25 {
				prod = <
					0 0x0001003c 0x00070000 0x00010000>;            //SDMMCAB_AUTO_CMD12_ERR_STATUS_0
			};
			prod_c_sdr50 {
				prod = <
					0 0x0001003c 0x00070000 0x00030000              //SDMMCAB_AUTO_CMD12_ERR_STATUS_0
					0 0x000101c0 0x0000e000 0x00008000>;            //SDMMCAB_VENDOR_TUNING_CNTRL0_0
			};
		};
	};

	sdhci@3460000 {
		prod-settings {
			#prod-cells = <4>;
			prod {
				prod = <
					0 0x00000004 0x00000fff 0x00000200              //SDMMCAB_BLOCK_SIZE_BLOCK_COUNT_0
					0 0x00000028 0x00000020 0x00000020              //SDMMCAB_POWER_CONTROL_HOST_0
					0 0x0000002c 0x000f0000 0x000e0000              //SDMMCAB_SW_RESET_TIMEOUT_CTRL_CLOCK_CONTROL_0
					0 0x00000100 0x1fff0048 0x05090000              //SDMMCAB_VENDOR_CLOCK_CNTRL_0
					0 0x00000104 0x80000000 0x00000000              //SDMMCAB_VENDOR_SYS_SW_CNTRL_0
					0 0x00000128 0x43000000 0x00000000              //SDMMCAB_VENDOR_MISC_CNTRL2_0
					0 0x000001c0 0x00001fc0 0x00000040              //SDMMCAB_VENDOR_TUNING_CNTRL0_0
					0 0x000001c4 0x0003ff77 0x00000400              //SDMMCAB_VENDOR_TUNING_CNTRL1_0
					0 0x000001e0 0x80000000 0x00000000              //SDMMCAB_SDMEMCOMPPADCTRL_0
					0 0x000001e4 0x20000000 0x20000000              //SDMMCAB_AUTO_CAL_CONFIG_0
					0 0x00000204 0x80000000 0x00000000              //SDMMCAB_VENDOR_MISC_CNTRL3_0
					0 0x00000218 0x80000000 0x00000000>;            //SDMMCAB_VENDOR_CQE_CNTRL1_0
			};
			prod_c_cqe_disabled {
				prod = <
					0 0x0000f008 0x00000001 0x00000000>;            //SDMMCAB_CQE_CQCFG_0
			};
			prod_c_cqe_enabled {
				prod = <
					0 0x0000f008 0x00000001 0x00000001>;            //SDMMCAB_CQE_CQCFG_0
			};
			prod_c_ddr50 {
				prod = <
					0 0x0000003c 0x00070000 0x00040000>;            //SDMMCAB_AUTO_CMD12_ERR_STATUS_0
			};
			prod_c_ddr50support_disabled {
				prod = <
					0 0x00000120 0x0000fffe 0x00000098>;            //SDMMCAB_VENDOR_MISC_CNTRL_0
			};
			prod_c_ddr50support_enabled {
				prod = <
					0 0x00000120 0x0000fffe 0x00000298>;            //SDMMCAB_VENDOR_MISC_CNTRL_0
			};
			prod_c_ddr52 {
				prod = <
					0 0x0000003c 0x00070000 0x00040000>;            //SDMMCAB_AUTO_CMD12_ERR_STATUS_0
			};
			prod_c_ds {
				prod = <
					0 0x0000003c 0x00070000 0x00000000>;            //SDMMCAB_AUTO_CMD12_ERR_STATUS_0
			};
			prod_c_esm {
				prod = <
					0 0x00000104 0x80000000 0x80000000>;            //SDMMCAB_VENDOR_SYS_SW_CNTRL_0
			};
			prod_c_hs {
				prod = <
					0 0x0000003c 0x00070000 0x00010000>;            //SDMMCAB_AUTO_CMD12_ERR_STATUS_0
			};
			prod_c_hs200 {
				prod = <
					0 0x0000003c 0x00070000 0x00030000              //SDMMCAB_AUTO_CMD12_ERR_STATUS_0
					0 0x000001c0 0x0000e000 0x00004000>;            //SDMMCAB_VENDOR_TUNING_CNTRL0_0
			};
			prod_c_hs400 {
				prod = <
					0 0x0000003c 0x00070000 0x00050000              //SDMMCAB_AUTO_CMD12_ERR_STATUS_0
					0 0x00000100 0x00000008 0x00000008              //SDMMCAB_VENDOR_CLOCK_CNTRL_0
					0 0x0000010c 0x00003f00 0x00003f00              //SDMMCAB_VENDOR_CAP_OVERRIDES_0
					0 0x000001c0 0x0000e000 0x00004000              //SDMMCAB_VENDOR_TUNING_CNTRL0_0
					0 0x000001e4 0x00007f7f 0x00000505>;            //SDMMCAB_AUTO_CAL_CONFIG_0
			};
			prod_c_hs533 {
				prod = <
					0 0x0000003c 0x00070000 0x00050000              //SDMMCAB_AUTO_CMD12_ERR_STATUS_0
					0 0x00000100 0x00000008 0x00000008              //SDMMCAB_VENDOR_CLOCK_CNTRL_0
					0 0x0000010c 0x00003f00 0x00002800              //SDMMCAB_VENDOR_CAP_OVERRIDES_0
					0 0x000001c0 0x0000e000 0x00002000              //SDMMCAB_VENDOR_TUNING_CNTRL0_0
					0 0x000001e4 0x00007f7f 0x00000505>;            //SDMMCAB_AUTO_CAL_CONFIG_0
			};
			prod_c_sdr104 {
				prod = <
					0 0x0000003c 0x00070000 0x00030000              //SDMMCAB_AUTO_CMD12_ERR_STATUS_0
					0 0x000001c0 0x0000e000 0x00004000>;            //SDMMCAB_VENDOR_TUNING_CNTRL0_0
			};
			prod_c_sdr12 {
				prod = <
					0 0x0000003c 0x00070000 0x00000000>;            //SDMMCAB_AUTO_CMD12_ERR_STATUS_0
			};
			prod_c_sdr25 {
				prod = <
					0 0x0000003c 0x00070000 0x00010000>;            //SDMMCAB_AUTO_CMD12_ERR_STATUS_0
			};
			prod_c_sdr50 {
				prod = <
					0 0x0000003c 0x00070000 0x00030000              //SDMMCAB_AUTO_CMD12_ERR_STATUS_0
					0 0x000001c0 0x0000e000 0x00008000>;            //SDMMCAB_VENDOR_TUNING_CNTRL0_0
			};
		};
	};
};
